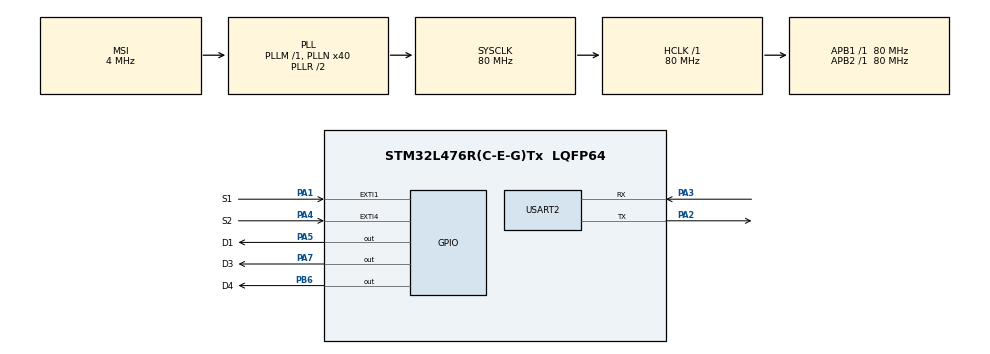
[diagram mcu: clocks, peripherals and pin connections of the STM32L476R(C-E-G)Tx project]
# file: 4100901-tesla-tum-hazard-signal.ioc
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Mcu.Family=STM32L4
Mcu.Name=STM32L476R(C-E-G)Tx
Mcu.Package=LQFP64
NVIC.EXTI1_IRQn=true\:0\:0\:false\:false\:true\:true\:true\:true
NVIC.EXTI4_IRQn=true\:0\:0\:false\:false\:true\:true\:true\:true
NVIC.PriorityGroup=NVIC_PRIORITYGROUP_4
PA1.GPIO_Label=S1
PA1.GPIO_ModeDefaultEXTI=GPIO_MODE_IT_FALLING
PA1.Signal=GPXTI1
PA2.Mode=Asynchronous
PA2.Signal=USART2_TX
PA3.Mode=Asynchronous
PA3.Signal=USART2_RX
PA4.GPIO_Label=S2
PA4.GPIO_ModeDefaultEXTI=GPIO_MODE_IT_FALLING
PA4.Signal=GPXTI4
PA5.GPIO_Label=D1
PA5.PinState=GPIO_PIN_SET
PA5.Signal=GPIO_Output
PA7.GPIO_Label=D3
PA7.PinState=GPIO_PIN_SET
PA7.Signal=GPIO_Output
PB6.GPIO_Label=D4
PB6.PinState=GPIO_PIN_SET
PB6.Signal=GPIO_Output
ProjectManager.HeapSize=0x200
ProjectManager.StackSize=0x400
ProjectManager.TargetToolchain=STM32CubeIDE
RCC.AHBFreq_Value=80000000
RCC.APB1Freq_Value=80000000
RCC.APB1TimFreq_Value=80000000
RCC.APB2Freq_Value=80000000
RCC.APB2TimFreq_Value=80000000
RCC.CortexFreq_Value=80000000
RCC.HCLKFreq_Value=80000000
RCC.HSE_VALUE=8000000
RCC.HSI_VALUE=16000000
RCC.LSE_VALUE=32768
RCC.MSI_VALUE=4000000
RCC.PLLN=40
RCC.SYSCLKFreq_VALUE=80000000
RCC.SYSCLKSource=RCC_SYSCLKSOURCE_PLLCLK
RCC.VCOOutputFreq_Value=160000000
USART2.VirtualMode-Asynchronous=VM_ASYNC
board=custom

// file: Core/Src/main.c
/* USER CODE BEGIN Header */
/**
  ******************************************************************************
  * @file           : main.c
  * @brief          : Main program body
  ******************************************************************************
  * @attention
  *
  * Copyright (c) 2024 STMicroelectronics.
  * All rights reserved.
  *
  * This software is licensed under terms that can be found in the LICENSE file
  * in the root directory of this software component.
  * If no LICENSE file comes with this software, it is provided AS-IS.
  *
  ******************************************************************************
  */
/* USER CODE END Header */
#include "main.h"

UART_HandleTypeDef huart2;

/* USER CODE BEGIN PV */
uint32_t left_toggles = 0;
/* USER CODE END PV */

void SystemClock_Config(void);
static void MX_GPIO_Init(void);
static void MX_USART2_UART_Init(void);
/* USER CODE BEGIN PFP */
void heartbeat(void);
/* USER CODE END PFP */

/* USER CODE BEGIN 0 */
void HAL_GPIO_EXIT_Callback(uint16_t GPIO_Pin)
{
	if (GPIO_Pin == S1_Pin) {
		HAL_UART_Transmit(&huart2, "S1\r\n", 4, 10);
		left_toggles = 6;
	}
}

void heartbeat(void)
{
	static uint32_t hearbeat_tick = 0;
	if (hearbeat_tick < HAL_GetTick())	{
		hearbeat_tick = HAL_GetTick() + 500;
		HAL_GPIO_TogglePin(D1_GPIO_Port, D1_Pin);
	}
}
/* USER CODE END 0 */
void turn_signal_left(void)
{
	static uint32_t turn_toggle_tick = 0;
	if (turn_toggle_tick < HAL_GetTick() && left_toggles > 0 {
		if (left_toggles > 0) {
			turn_toogle_tick = HAL_GetTick() + 500;
			HAL_GPIO_TogglePin(D3_GPIO_Port, D3_Pin);
			left_toggles--;
		} else {
			HAL_GPIO_WritePin(D3_GPIO_Port, D3_Pin, 1);
		}
	}
}
int main(void)
{

  /* MCU Configuration--------------------------------------------------------*/

  /* Reset of all peripherals, Initializes the Flash interface and the Systick. */
  HAL_Init();

  /* Configure the system clock */
  SystemClock_Config();

  /* Initialize all configured peripherals */
  MX_GPIO_Init();
  MX_USART2_UART_Init();

  /* Infinite loop */
  while (1)
  {
	  heartbeat();
  }
}

void SystemClock_Config(void)
{
  RCC_OscInitTypeDef RCC_OscInitStruct = {0};
  RCC_ClkInitTypeDef RCC_ClkInitStruct = {0};

  /** Configure the main internal regulator output voltage
  */
  if (HAL_PWREx_ControlVoltageScaling(PWR_REGULATOR_VOLTAGE_SCALE1) != HAL_OK)
  {
    Error_Handler();
  }

  /** Initializes the RCC Oscillators according to the specified parameters
  * in the RCC_OscInitTypeDef structure.
  */
  RCC_OscInitStruct.OscillatorType = RCC_OSCILLATORTYPE_MSI;
  RCC_OscInitStruct.MSIState = RCC_MSI_ON;
  RCC_OscInitStruct.MSICalibrationValue = 0;
  RCC_OscInitStruct.MSIClockRange = RCC_MSIRANGE_6;
  RCC_OscInitStruct.PLL.PLLState = RCC_PLL_ON;
  RCC_OscInitStruct.PLL.PLLSource = RCC_PLLSOURCE_MSI;
  RCC_OscInitStruct.PLL.PLLM = 1;
  RCC_OscInitStruct.PLL.PLLN = 40;
  RCC_OscInitStruct.PLL.PLLP = RCC_PLLP_DIV7;
  RCC_OscInitStruct.PLL.PLLQ = RCC_PLLQ_DIV2;
  RCC_OscInitStruct.PLL.PLLR = RCC_PLLR_DIV2;
  if (HAL_RCC_OscConfig(&RCC_OscInitStruct) != HAL_OK)
  {
    Error_Handler();
  }

  /** Initializes the CPU, AHB and APB buses clocks
  */
  RCC_ClkInitStruct.ClockType = RCC_CLOCKTYPE_HCLK|RCC_CLOCKTYPE_SYSCLK
                              |RCC_CLOCKTYPE_PCLK1|RCC_CLOCKTYPE_PCLK2;
  RCC_ClkInitStruct.SYSCLKSource = RCC_SYSCLKSOURCE_PLLCLK;
  RCC_ClkInitStruct.AHBCLKDivider = RCC_SYSCLK_DIV1;
  RCC_ClkInitStruct.APB1CLKDivider = RCC_HCLK_DIV1;
  RCC_ClkInitStruct.APB2CLKDivider = RCC_HCLK_DIV1;

  if (HAL_RCC_ClockConfig(&RCC_ClkInitStruct, FLASH_LATENCY_4) != HAL_OK)
  {
    Error_Handler();
  }
}

static void MX_USART2_UART_Init(void)
{

  huart2.Instance = USART2;
  huart2.Init.BaudRate = 115200;
  huart2.Init.WordLength = UART_WORDLENGTH_8B;
  huart2.Init.StopBits = UART_STOPBITS_1;
  huart2.Init.Parity = UART_PARITY_NONE;
  huart2.Init.Mode = UART_MODE_TX_RX;
  huart2.Init.HwFlowCtl = UART_HWCONTROL_NONE;
  huart2.Init.OverSampling = UART_OVERSAMPLING_16;
  huart2.Init.OneBitSampling = UART_ONE_BIT_SAMPLE_DISABLE;
  huart2.AdvancedInit.AdvFeatureInit = UART_ADVFEATURE_NO_INIT;
  if (HAL_UART_Init(&huart2) != HAL_OK)
  {
    Error_Handler();
  }

}

static void MX_GPIO_Init(void)
{
  GPIO_InitTypeDef GPIO_InitStruct = {0};

  /* GPIO Ports Clock Enable */
  __HAL_RCC_GPIOA_CLK_ENABLE();
  __HAL_RCC_GPIOB_CLK_ENABLE();

  /*Configure GPIO pin Output Level */
  HAL_GPIO_WritePin(GPIOA, D1_Pin|D3_Pin, GPIO_PIN_SET);

  /*Configure GPIO pin Output Level */
  HAL_GPIO_WritePin(D4_GPIO_Port, D4_Pin, GPIO_PIN_SET);

  /*Configure GPIO pins : S1_Pin S2_Pin */
  GPIO_InitStruct.Pin = S1_Pin|S2_Pin;
  GPIO_InitStruct.Mode = GPIO_MODE_IT_FALLING;
  GPIO_InitStruct.Pull = GPIO_NOPULL;
  HAL_GPIO_Init(GPIOA, &GPIO_InitStruct);

  /*Configure GPIO pins : D1_Pin D3_Pin */
  GPIO_InitStruct.Pin = D1_Pin|D3_Pin;
  GPIO_InitStruct.Mode = GPIO_MODE_OUTPUT_PP;
  GPIO_InitStruct.Pull = GPIO_NOPULL;
  GPIO_InitStruct.Speed = GPIO_SPEED_FREQ_LOW;
  HAL_GPIO_Init(GPIOA, &GPIO_InitStruct);

  /*Configure GPIO pin : D4_Pin */
  GPIO_InitStruct.Pin = D4_Pin;
  GPIO_InitStruct.Mode = GPIO_MODE_OUTPUT_PP;
  GPIO_InitStruct.Pull = GPIO_NOPULL;
  GPIO_InitStruct.Speed = GPIO_SPEED_FREQ_LOW;
  HAL_GPIO_Init(D4_GPIO_Port, &GPIO_InitStruct);

  /* EXTI interrupt init*/
  HAL_NVIC_SetPriority(EXTI1_IRQn, 0, 0);
  HAL_NVIC_EnableIRQ(EXTI1_IRQn);

  HAL_NVIC_SetPriority(EXTI4_IRQn, 0, 0);
  HAL_NVIC_EnableIRQ(EXTI4_IRQn);

}

void Error_Handler(void)
{
  __disable_irq();
  while (1)
  {
  }
}
